# RL7005_IP_SVD register map
Vendor: Realtek
Registers are 32-bit, read-write, reset 0x0 unless marked. A register's access mark holds for its fields unless they carry their own. Offsets are from the block's base; [hi:lo] are bit positions; <NAME> marks a mode.

## SWR_REG
Base 0x4080A180
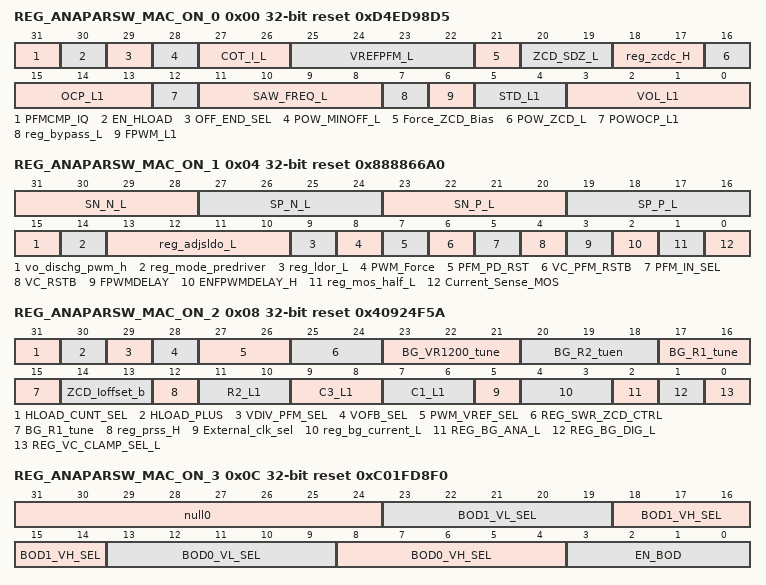
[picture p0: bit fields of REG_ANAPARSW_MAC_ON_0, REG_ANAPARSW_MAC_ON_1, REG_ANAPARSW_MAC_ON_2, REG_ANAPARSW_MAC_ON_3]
0x00 REG_ANAPARSW_MAC_ON_0 access per field reset 0xD4ED98D5
  [31] PFMCMP_IQ rw — PFM comparator bias, 0: 50nA 1:250nA
  [30] EN_HLOAD rw — Enable Heavy load counter
  [29] OFF_END_SEL rw — COT off time controlled by, 0: ZCD 1: min off time
  [28] POW_MINOFF_L rw — 0:normal current 1:increase OCP cmp current
  [27:26] COT_I_L rw — COT ON Current 00:150nA 01:150nA+100nA 10:150nA+150nA 11:150nA+250nA
  [25:22] VREFPFM_L rw — SWR/LDO SEL <93>=0 <93>=1 0000 0.495 0.458 0001 0.654 0.610 0010 0.707 0.662 0011 0.760 0.712 0100 0.795 0.746 0101 0.848 0.797 0110 0.883 0.831 0111 0.954 0.899 1000 1.042 0.984 1001 1.131 1.069 1010 1.219 1.153 1011 1.255 1.188 1100 1.308 1.238 1101 1.343 1.272 1110 1.414 1.340 1111 1.503 1.425
  [21] Force_ZCD_Bias rw — 0:ZCD bias on after SS 1:ZCD bias on when ZCD enable
  [20:19] ZCD_SDZ_L rw — Increase ZCD delay cell
  [18:17] reg_zcdc_H ro — 00:0.1u 01:0.2u(PFM) 10:0.7u(PWM) 11:0.8u
  [16] POW_ZCD_L rw — Enable ZCD
  [15:13] OCP_L1 rw — PWM current (A) PFM current (A) mP 000 0.533 0.105 001 0.580 0.145 010 0.630 0.185 011 0.680 0.223 100 0.730 0.263 101 0.780 0.303 110 0.830 0.342 111 0.890 0.290(VIN/10)
  [12] POWOCP_L1 rw — POWOCP_L1=1=> enable over current protection
  [11:8] SAW_FREQ_L ro — 0000 458.0k 0001 680.2k 0010 898.9k 0011 1.113M 0100 1.321M 0101 1.522M 0110 1.716M 0111 1.902M 1000 2.087M 1001 2.258M 1010 2.426M 1011 2.582M 1100 2.743M 1101 2.888M 1110 3.035M 1111 3.165M
  [7] reg_bypass_L rw — 1:bypass SSR latch
  [6] FPWM_L1 rw — FPWM_L1 = 1 => force PWM FPWM_L1 = 0 => force PFM
  [5:4] STD_L1 rw — STD_L1<1:0> time 750u 1.5m 10 3m 11 6m
  [3:0] VOL_L1 rw — VREF 0.6 0.635 0.835 0.865 Code VOUT VOUT VOUT VOUT 1111 1.028571 1.088571 1.431429 1.482857 1110 1 1.058333 1.391667 1.441667 1101 0.972973 1.02973 1.354054 1.402703 1100 0.947368 1.002632 1.318421 1.365789 1011 0.935065 0.98961 1.301299 1.348052 1010 0.923077 0.976923 1.284615 1.330769 1001 0.911392 0.964557 1.268354 1.313924 1000 0.9 0.9525 1.2525 1.2975 0111 0.888889 0.940741 1.237037 1.281481 0110 0.878049 0.929268 1.221951 1.265854 0101 0.86747 0.918072 1.207229 1.250602 0100 0.847059 0.896471 1.178824 1.221176 0011 0.827586 0.875862 1.151724 1.193103 0010 0.808989 0.85618 1.125843 1.166292 0001 0.791209 0.837363 1.101099 1.140659 0000 0.774194 0.819355 1.077419 1.116129
0x04 REG_ANAPARSW_MAC_ON_1 access per field reset 0x888866A0
  [31:28] SN_N_L rw — NGATE NMOS driving
  [27:24] SP_N_L rw — NGATE PMOS driving
  [23:20] SN_P_L rw — PGATE NMOS driving
  [19:16] SP_P_L rw — PGATE PMOS driving
  [15] vo_dischg_pwm_h rw — `
  [14] reg_mode_predriver rw — 1:3 level predriver
  [13:10] reg_adjsldo_L rw — 0000 1.043 0001 1.075 0010 1.108 0011 1.143 0100 1.180 0101 1.220 0110 1.263 0111 1.286 1000 1.309 1001 1.333 1010 1.359 1011 1.385 1100 1.412 1101 1.444 1110 1.469 1111 1.500
  [9] reg_ldor_L rw — 1:ldos res short
  [8] PWM_Force rw — 0: PWM bias enabled only at PWM mode 1: Force PWM bias enable when in PWM/PFM mode
  [7] PFM_PD_RST rw — 1: When leave PFM mode, COT logic is reset
  [6] VC_PFM_RSTB rw — When into PFM, VC is, 0: clamped (bit 40 also =1) 1. floating
  [5] PFM_IN_SEL rw — Power MOS into PFM when PFM CTRL, 0: rising 1: falling
  [4] VC_RSTB rw — Before SS VC is, 0: pulled low 1: floating
  [3] FPWMDELAY rw — 1:PFM<=>PWM PFM/PWM change by using DFF(CKMOD)
  [2] ENFPWMDELAY_H rw — 1:PFM=>PWM delay PWM enable and wait one clock cycle then PFM off
  [1] reg_mos_half_L ro — 1:power mos half
  [0] Current_Sense_MOS rw — 1: current sensing MOS for large OC current
0x08 REG_ANAPARSW_MAC_ON_2 access per field reset 0x40924F5A
  [31] HLOAD_CUNT_SEL rw — Dummy
  [30] HLOAD_PLUS rw — Dummy
  [29] VDIV_PFM_SEL rw — Dummy
  [28] VOFB_SEL rw — 0:Feedback from REGU Internal PAD for 1.25V/1.35V 1:Feedback from External PAD for 0.9V/1.0V
  [27:26] PWM_VREF_SEL ro — 00:VREF=0.600 01:VREF=0.635 10:VREF=0.835 11:VREF=0.865
  [25:24] REG_SWR_ZCD_CTRL ro — // SWR ZCD CTRL control <1>1:double current <0>1'b1: force in CCM/DCM boundary mode(default), 1'b0 : no boundary
  [23:21] BG_VR1200_tune rw — BG電壓調整
  [20:18] BG_R2_tuen rw — BG R2電阻調整
  [17:15] BG_R1_tune rw — BG R1電阻調整
  [14:13] ZCD_Ioffset_b ro — 00=>+600nA 01=>+400nA 10=>+200nA 11=>0nA
  [12] reg_prss_H ro — 0:default 1:res+cap improve psrr
  [11:10] R2_L1 rw — 00 => 0.4M 01 => 0.3M 10 => 0.2M 11 => 0.1M
  [9:8] C3_L1 rw — 00 => 1.59p 01 => 3.2p 10 => 4.76p 11 => 6.34p
  [7:6] C1_L1 rw — 00 => 1.03p 01 => 2.06p 10 => 3.1p 11 => 4.12p
  [5] External_clk_sel rw — 0:internal clock 1:external clock
  [4:3] reg_bg_current_L rw — 00:23.9n 01:54.6n 10:117.8n
  [2] REG_BG_ANA_L rw — 1:External SWR BG switch on
  [1] REG_BG_DIG_L rw — 1:Local SWR BG switch on
  [0] REG_VC_CLAMP_SEL_L rw — 0:unity gain feedback clamp VC=VREF 1.orignal clamp(roll back option)
0x0C REG_ANAPARSW_MAC_ON_3 reset 0xC01FD8F0
  [31:24] null0 — NO use in RL6973
  [23:19] BOD1_VL_SEL — NO use in RL6973
  [18:14] BOD1_VH_SEL — NO use in RL6973
  [13:9] BOD0_VL_SEL — dummy
  [8:4] BOD0_VH_SEL — dummy
  [3:0] EN_BOD — dummy
0x10 REG_ANAPARSW_MAC_ON_4 reset 0x410
  [31:0] null1 — NO use in RL6973
0x14 REG_ANAPARSW_MAC_ON_5 reset 0xFF
  [7:0] null2 — NO use in RL6973
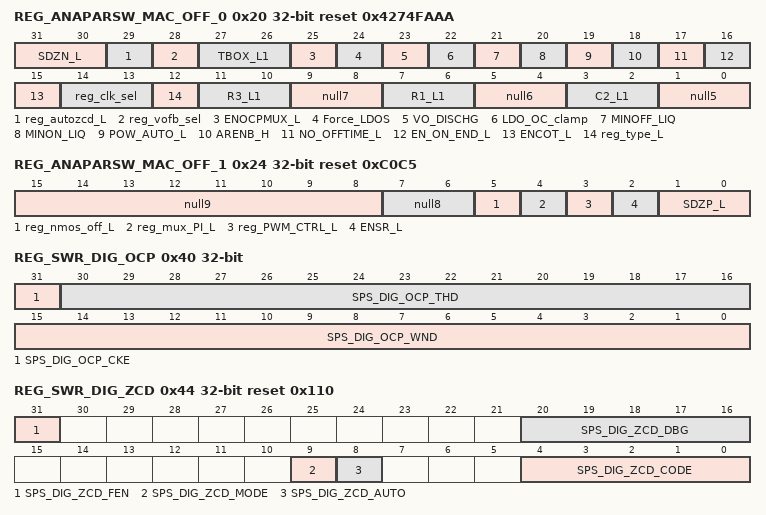
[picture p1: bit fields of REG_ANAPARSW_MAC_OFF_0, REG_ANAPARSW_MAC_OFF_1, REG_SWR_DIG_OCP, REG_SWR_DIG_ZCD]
0x20 REG_ANAPARSW_MAC_OFF_0 reset 0x4274FAAA
  [31:30] SDZN_L — Nonoverlap delay cell for NMOS
  [29] reg_autozcd_L — 0:register 1:10000
  [28] reg_vofb_sel — 0:vo15 1:LX_SPS
  [27:26] TBOX_L1 — TBOX_L1<1:0> output 00 CKOVER/RAMPOVER 01 NI/PI 10 CKSS/SSOVER 11 i/NIOFF_H
  [25] ENOCPMUX_L — 1:OCP signal control by MUX 0:OCP signal control by I
  [24] Force_LDOS — 1:LDOS force on
  [23] VO_DISCHG — 1:VO with 1mA discharge
  [22] LDO_OC_clamp — 0:OC clamp with P/NMOS 1:OC clamp with PMOS
  [21] MINOFF_LIQ — 0:Min. off circuit always on 1:Min. off circuit pulse on
  [20] MINON_LIQ — 0:Min. on circuit always on 1:Min. on circuit pulse on
  [19] POW_AUTO_L — 1:auto PFM/PWM 0:register control
  [18] ARENB_H — 1:off 0:on
  [17] NO_OFFTIME_L — 0:from min OFF time(PFM COT) 1:always on
  [16] EN_ON_END_L — 1:EN min OFF time (PFM COT)
  [15] ENCOT_L — 1:PFM COT
  [14:13] reg_clk_sel — 00:out of phase CKSS 01:out of phase PWM_CTRIL 10:ckout 11:HG
  [12] reg_type_L — 1:type3 0:type2
  [11:10] R3_L1 — 00 => 36k 01 => 30k 10 => 24k 11 => 24k
  [9:8] null7
  [7:6] R1_L1 — 00 => 900k 01 => 720k 10 => 900k 11 => 1080k
  [5:4] null6
  [3:2] C2_L1 — 00 => 13f 01 => 26f 10 => 39f 11 => 41f
  [1:0] null5
0x24 REG_ANAPARSW_MAC_OFF_1 access per field reset 0xC0C5
  [15:8] null9 rw — dummy
  [7:6] null8 rw — dummy
  [5] reg_nmos_off_L ro — 0:normal 1:NMOS always off
  [4] reg_mux_PI_L rw — 1:PI (original) 0:i
  [3] reg_PWM_CTRL_L rw — 0:internal PWM 1:external PWM
  [2] ENSR_L rw — 1:with SSR latch
  [1:0] SDZP_L rw — Nonoverlap delay cell for PMOS
0x40 REG_SWR_DIG_OCP
  [31] SPS_DIG_OCP_CKE — SPS OCP clock enable,used as function enable
  [30:16] SPS_DIG_OCP_THD — SPS OCP event threshold
  [15:0] SPS_DIG_OCP_WND — SPS OCP time window
0x44 REG_SWR_DIG_ZCD access per field reset 0x110
  [31] SPS_DIG_ZCD_FEN rw — zcd function enable
  [20:16] SPS_DIG_ZCD_DBG ro — The acture zcd code used for SPS core
  [9] SPS_DIG_ZCD_MODE rw — SPS ZCD SW mode enable
  [8] SPS_DIG_ZCD_AUTO rw — SPS HW ZCD code auto count function enable
  [4:0] SPS_DIG_ZCD_CODE rw — SPS_DIG_ZCD_CODE,this is used for SW mode
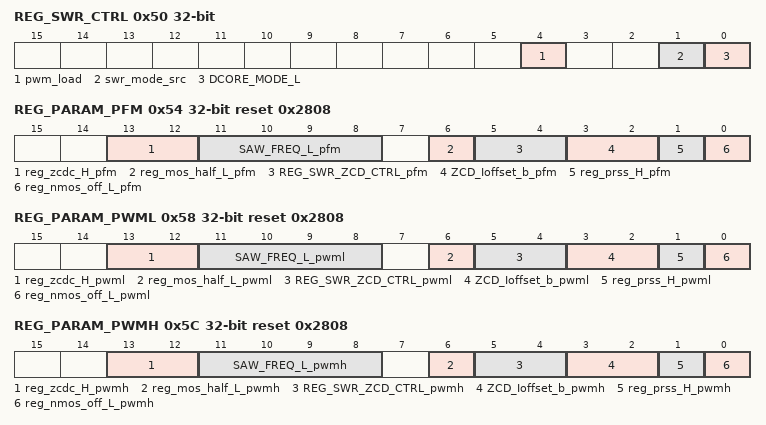
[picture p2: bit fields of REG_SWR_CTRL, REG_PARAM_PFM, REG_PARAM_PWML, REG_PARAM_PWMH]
0x50 REG_SWR_CTRL access per field
  [4] pwm_load ro — SWR pwm loading(scan value is 0) 1:heavy 0:light
  [1] swr_mode_src rw — Select SWR mode ctrl source to determine SWR parameter 1: from Analog mode flag , which is 0x50[0] 0: from D->A mode control bit (Note , scan value is 1:PWM)
  [0] DCORE_MODE_L ro — SWR mode flag 1: PWM 0: PFM
0x54 REG_PARAM_PFM reset 0x2808
  [13:12] reg_zcdc_H_pfm — 00:0.1u 01:0.2u(PFM) 10:0.7u(PWM) 11:0.8u
  [11:8] SAW_FREQ_L_pfm — 0000 458.0k 0001 680.2k 0010 898.9k 0011 1.113M 0100 1.321M 0101 1.522M 0110 1.716M 0111 1.902M 1000 2.087M 1001 2.258M 1010 2.426M 1011 2.582M 1100 2.743M 1101 2.888M 1110 3.035M 1111 3.165M
  [6] reg_mos_half_L_pfm — 1:power mos half
  [5:4] REG_SWR_ZCD_CTRL_pfm — // SWR ZCD CTRL control <1>1:double current <0>1'b1: force in CCM/DCM boundary mode(default), 1'b0 : no boundary
  [3:2] ZCD_Ioffset_b_pfm — 00=>+600nA 01=>+400nA 10=>+200nA 11=>0nA
  [1] reg_prss_H_pfm — 0:default 1:res+cap improve psrr
  [0] reg_nmos_off_L_pfm — 0:normal 1:NMOS always off
0x58 REG_PARAM_PWML reset 0x2808
  [13:12] reg_zcdc_H_pwml — 00:0.1u 01:0.2u(PFM) 10:0.7u(PWM) 11:0.8u
  [11:8] SAW_FREQ_L_pwml — 0000 458.0k 0001 680.2k 0010 898.9k 0011 1.113M 0100 1.321M 0101 1.522M 0110 1.716M 0111 1.902M 1000 2.087M 1001 2.258M 1010 2.426M 1011 2.582M 1100 2.743M 1101 2.888M 1110 3.035M 1111 3.165M
  [6] reg_mos_half_L_pwml — 1:power mos half
  [5:4] REG_SWR_ZCD_CTRL_pwml — // SWR ZCD CTRL control <1>1:double current <0>1'b1: force in CCM/DCM boundary mode(default), 1'b0 : no boundary
  [3:2] ZCD_Ioffset_b_pwml — 00=>+600nA 01=>+400nA 10=>+200nA 11=>0nA
  [1] reg_prss_H_pwml — 0:default 1:res+cap improve psrr
  [0] reg_nmos_off_L_pwml — 0:normal 1:NMOS always off
0x5C REG_PARAM_PWMH reset 0x2808
  [13:12] reg_zcdc_H_pwmh — 00:0.1u 01:0.2u(PFM) 10:0.7u(PWM) 11:0.8u
  [11:8] SAW_FREQ_L_pwmh — 0000 458.0k 0001 680.2k 0010 898.9k 0011 1.113M 0100 1.321M 0101 1.522M 0110 1.716M 0111 1.902M 1000 2.087M 1001 2.258M 1010 2.426M 1011 2.582M 1100 2.743M 1101 2.888M 1110 3.035M 1111 3.165M
  [6] reg_mos_half_L_pwmh — 1:power mos half
  [5:4] REG_SWR_ZCD_CTRL_pwmh — // SWR ZCD CTRL control <1>1:double current <0>1'b1: force in CCM/DCM boundary mode(default), 1'b0 : no boundary
  [3:2] ZCD_Ioffset_b_pwmh — 00=>+600nA 01=>+400nA 10=>+200nA 11=>0nA
  [1] reg_prss_H_pwmh — 0:default 1:res+cap improve psrr
  [0] reg_nmos_off_L_pwmh — 0:normal 1:NMOS always off
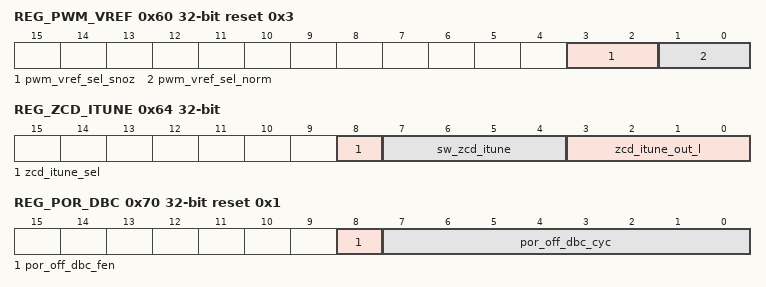
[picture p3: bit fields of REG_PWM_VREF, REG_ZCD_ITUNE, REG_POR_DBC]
0x60 REG_PWM_VREF reset 0x3
  [3:2] pwm_vref_sel_snoz — For snooze mode power , it use pwm 0.8v and CLDO pc mode , to select PWM 0.8v , it must change vref
  [1:0] pwm_vref_sel_norm — PWM default vref
0x64 REG_ZCD_ITUNE access per field
  [8] zcd_itune_sel rw — Select itune code source 1: from software config 0: auto by regu self
  [7:4] sw_zcd_itune rw — Software config zcd itune code
  [3:0] zcd_itune_out_l ro — SWR output ZCD itune code
0x70 REG_POR_DBC reset 0x1
  [8] por_off_dbc_fen — Enable POR_OFF debounce
  [7:0] por_off_dbc_cyc — POR_OFF debounce cycle , base in 100K clock period
0x7C REG_DUMMY reset 0xF
  [7:0] dummy
